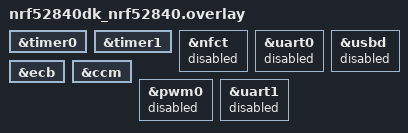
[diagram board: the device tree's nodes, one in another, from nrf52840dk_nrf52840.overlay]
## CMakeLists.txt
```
cmake_minimum_required(VERSION 3.20.0)
find_package(Zephyr REQUIRED HINTS $ENV{ZEPHYR_BASE})

project(periodic_adv_sender)

target_sources(app PRIVATE src/main.c src/saadc_helpers.c src/timer_helpers.c src/bt_helpers.c)
```

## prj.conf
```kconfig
CONFIG_BT=y
CONFIG_BT_BROADCASTER=y
CONFIG_BT_EXT_ADV=y
CONFIG_BT_PER_ADV=y
CONFIG_BT_DEVICE_NAME="harry"
CONFIG_BT_PER_ADV_SYNC_TRANSFER_SENDER=y
CONFIG_BT_PER_ADV_RSP=y

CONFIG_BT_MAX_CONN=1
CONFIG_BT_CENTRAL=y
CONFIG_BT_PRIVACY=y
CONFIG_BT_SMP=y

CONFIG_BT_CTLR_TX_PWR_MINUS_20=y

# Config SAADC
#CONFIG_GPIO=n
CONFIG_NRFX_GPIOTE=y
CONFIG_NRFX_SAADC=y


# Config Timers
CONFIG_NRFX_TIMER0=y
CONFIG_NRFX_TIMER1=y


# power saving stuff
CONFIG_LOG=n
CONFIG_SERIAL=n
CONFIG_TFM_LOG_LEVEL_SILENCE=y


# Enable system power management
CONFIG_PM=y
CONFIG_PM_DEVICE=y



#DEBUG
#CONFIG_DEBUG_THREAD_INFO=y
#CONFIG_DEBUG_INFO=y
#CONFIG_THREAD_RUNTIME_STATS=y
#CONFIG_DEBUG_OPTIMIZATIONS=y
#CONFIG_ASSERT=y
#CONFIG_THREAD_NAME=y
#CONFIG_THREAD_ANALYZER=y
#CONFIG_THREAD_MONITOR=y

# enable uart driver
#CONFIG_SERIAL=y

# enable console
#CONFIG_CONSOLE=y
#CONFIG_UART_CONSOLE=y

# Enable RTT
#CONFIG_USE_SEGGER_RTT=y




# Enable minimal libc
CONFIG_MINIMAL_LIBC=y
CONFIG_MINIMAL_LIBC_MALLOC=y
# Set the malloc arena size to a non-zero value
CONFIG_MINIMAL_LIBC_MALLOC_ARENA_SIZE=1024
```

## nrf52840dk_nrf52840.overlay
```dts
// To get started, press Ctrl+Space to bring up the completion menu and view the available nodes.

// You can also use the buttons in the sidebar to perform actions on nodes.
// Actions currently available include:

// * Enabling / disabling the node
// * Adding the bus to a bus
// * Removing the node
// * Connecting ADC channels

// For more help, browse the DeviceTree documentation at https://docs.zephyrproject.org/latest/guides/dts/index.html
// You can also visit the nRF DeviceTree extension documentation at https://docs.nordicsemi.com/bundle/nrf-connect-vscode/page/guides/ncs_configure_app.html#devicetree-support-in-the-extension

&timer0 {
	status = "okay";
};

&timer1 {
	status = "okay";
};

// was disabled
&nfct {
	status = "disabled";
};

// was disabled
&uart0 {
	status = "disabled";
};

// was disabled
&usbd {
	status = "disabled";
};

// was okay
&ecb {
	status = "okay";
};

// was okay
&ccm {
	status = "okay";
};

// was disabled
&pwm0 {
	status = "disabled";
};

// was disabled
&uart1 {
	status = "disabled";
};
```

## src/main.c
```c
/*
 * Copyright (c) 2023 Nordic Semiconductor ASA
 *
 * SPDX-License-Identifier: Apache-2.0
 */

#include "timer_helpers.h"
#include "bt_helpers.h"
#include "saadc_helpers.h"
#include <stdlib.h>
#include <ram_pwrdn.h>
#include <zephyr/pm/device.h>

/*
================================
=#=#=#= Global Variables =#=#=#=
================================
*/

uint8_t backing_store[NUM_SUBEVENTS][PACKET_SIZE];


BUILD_ASSERT(ARRAY_SIZE(backing_store) == ARRAY_SIZE(subevent_data_params));



/*
================================
=#=#=#= HELPER FUNCTIONS =#=#=#=
================================
*/


void saadc_sample() {
	saadc_result res_se = {CHANNEL_COUNT_SE, malloc(sizeof(saadc_result) * CHANNEL_COUNT_SE)};
	sample_saadc(SE, &res_se);
	int i = 0;
	/*
	while(i < res_se.nchannels) {
		backing_store[i][0] = (uint8_t) i;
		backing_store[i][1] = (uint8_t) res_se.values[i];
		printk("Channel %d: %d\n", i, (int) res_se.values[i]);
		i++;
	}*/
	

	backing_store[0][0] = (uint8_t) res_se.values[0]; // ADC channel 0
	backing_store[0][1] = (uint8_t) res_se.values[1]; // ADC channel 1
	backing_store[0][2] = (uint8_t) res_se.values[2]; // ADC channel 2
	backing_store[0][3] = (uint8_t) res_se.values[3]; // ADC channel 3

	while(i < res_se.nchannels) {
		int val = res_se.values[i];
		printk("SINGLE ENDED - Channel %d: %d (%d V, or %d mV)\n", i, (int) val, to_volts(val), to_millivolts(val));
		i++;
	}

	saadc_result res_diff = {CHANNEL_COUNT_SE, malloc(sizeof(saadc_result) * CHANNEL_COUNT_DIFF)};

	sample_saadc(DIFF, &res_diff);

	backing_store[0][4] = (uint8_t) res_diff.values[0]; // ADC channels 0 & 1
	backing_store[0][5] = (uint8_t) res_diff.values[1]; // ADC channels 2 & 3
	backing_store[0][6] = (uint8_t) res_diff.values[2]; // ADC channels 4 & 5
	backing_store[0][7] = (uint8_t) res_diff.values[3]; // ADC channels 6 & 7


	i = 0;
	while(i < res_diff.nchannels) {
		// Offset by the number of channels in the single-ended sample
		//backing_store[i + res_se.nchannels][0] = (uint8_t) i;
		//backing_store[i + res_se.nchannels][1] = (uint8_t) res_diff.values[i];
		printk("DIFFERENTIAL - Channel %d: %d\n", i, (int) res_diff.values[i]);
		i++;
	}
}

int main(void) {
	//nrf_uart_disable(NRF_UART0);

//	const auto * qspi_dev = DEVICE_DT_GET(DT_INST(0, nordic_qspi_nor));
//	if (device_is_ready(qspi_dev))
//	{
//		// Put the peripheral into suspended state.
//		pm_device_action_run(qspi_dev, PM_DEVICE_ACTION_SUSPEND);
//	}


	nrfx_timer_t timer = NRFX_TIMER_INSTANCE(TIMER_INST_IDX);
	nrfx_timer_config_t config = NRFX_TIMER_DEFAULT_CONFIG;
	config.bit_width = NRF_TIMER_BIT_WIDTH_32;
	bool flag = 0;
	config.p_context = &flag;
	/*{
		.frequency = NRF_TIMER_FREQ_16MHz,         						///< Frequency.
		.mode = NRF_TIMER_MODE_TIMER,           					    ///< Mode of operation.
		.bit_width = NRF_TIMER_BIT_WIDTH_32,        				  	///< Bit width.
		.interrupt_priority = NRFX_TIMER_DEFAULT_CONFIG_IRQ_PRIORITY, 	///< Interrupt priority.
		.p_context = NULL												///< Context passed to interrupt handler.
	};*/
	
	saadc_sample();
	k_sleep(K_MSEC(400));

	bool err = initialise_bt(backing_store);
	if (err) return 1;

	k_sleep(K_MSEC(800));

	timer_setup(&timer, &config);

	while (true) {
		if (flag) {
			saadc_sample();
			update_bufs(backing_store);
			k_sleep(K_MSEC(5000));
			flag = 0;
			//bt_disable();
		}
		k_sleep(K_MSEC(5000));
		//power_down_unused_ram();
	}

	return 0;
}
```

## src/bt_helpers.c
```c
/*
 * Copyright (c) 2023 Nordic Semiconductor ASA
 *
 * SPDX-License-Identifier: Apache-2.0
 */


#include "bt_helpers.h"


const struct bt_le_per_adv_param per_adv_params = {
	.interval_min = PER_ADV_INTERVAL,
	.interval_max = PER_ADV_INTERVAL,
	.options = 0, //(BT_LE_PER_ADV_OPT_USE_TX_POWER | BT_LE_PER_ADV_OPT_INCLUDE_ADI),
	.num_subevents = NUM_SUBEVENTS,
	.subevent_interval = SUBEVENT_INTERVAL,
	.response_slot_delay = 0x5,
	.response_slot_spacing = 0x50,
	.num_response_slots = NUM_RSP_SLOTS,
};

const struct bt_le_adv_param* adv_params = BT_LE_EXT_ADV_NCONN_NAME; //BT_LE_ADV_PARAM((BT_LE_ADV_OPT_EXT_ADV | BT_LE_ADV_OPT_USE_NAME), ADVERTISING_INTERVAL, ADVERTISING_INTERVAL, NULL);

struct bt_conn *default_conn;
struct net_buf_simple bufs[NUM_SUBEVENTS];
struct bt_le_per_adv_subevent_data_params subevent_data_params[NUM_SUBEVENTS];

BUILD_ASSERT(ARRAY_SIZE(bufs) == ARRAY_SIZE(subevent_data_params));

// Function to handle the request for data from the receiver.
void request_cb(struct bt_le_ext_adv *adv, const struct bt_le_per_adv_data_request *request) {
	int err;
	uint8_t to_send;

	/* Continuously send the data in bufs and listen to all response slots */

	to_send = MIN(request->count, ARRAY_SIZE(subevent_data_params));
	for (size_t i = 0; i < to_send; i++) {
		subevent_data_params[i].subevent =
			(request->start + i) % per_adv_params.num_subevents;
		subevent_data_params[i].response_slot_start = 0;
		subevent_data_params[i].response_slot_count = NUM_RSP_SLOTS;
		subevent_data_params[i].data = &bufs[i];
	}

	err = bt_le_per_adv_set_subevent_data(adv, to_send, subevent_data_params);
	if (err) {
		printk("Failed to set subevent data (err %d)\n", err);
	}
}

bool get_address(struct bt_data *data, void *user_data) {
	bt_addr_le_t *addr = user_data;

	if (data->type == BT_DATA_LE_BT_DEVICE_ADDRESS) {
		memcpy(addr->a.val, data->data, sizeof(addr->a.val));
		addr->type = data->data[sizeof(addr->a)];

		return false;
	}

	return true;
}

void response_cb(struct bt_le_ext_adv *adv, struct bt_le_per_adv_response_info *info,
			struct net_buf_simple *buf)
{
	int err;
	bt_addr_le_t peer;
	char addr_str[BT_ADDR_LE_STR_LEN];
	struct bt_conn_le_create_synced_param synced_param;
	struct bt_le_conn_param conn_param;

	if (!buf) {
		return;
	}

	if (default_conn) {
		/* Do not initiate new connections while already connected */
		return;
	}

	bt_addr_le_copy(&peer, &bt_addr_le_none);
	bt_data_parse(buf, get_address, &peer);
	if (bt_addr_le_eq(&peer, &bt_addr_le_none)) {
		/* No address found */
		return;
	}

	bt_addr_le_to_str(&peer, addr_str, sizeof(addr_str));
	printk("Connecting to %s in subevent %d\n", addr_str, info->subevent);

	synced_param.peer = &peer;
	synced_param.subevent = info->subevent;

	/* Choose same interval as PAwR advertiser to avoid scheduling conflicts */
	conn_param.interval_min = SUBEVENT_INTERVAL;
	conn_param.interval_max = SUBEVENT_INTERVAL;

	/* Default values */
	conn_param.latency = 0;
	conn_param.timeout = 400;

	err = bt_conn_le_create_synced(adv, &synced_param, &conn_param, &default_conn);
	if (err) {
		printk("Failed to initiate connection (err %d)", err);
	}
	//bt_le_adv_stop();
}

const struct bt_le_ext_adv_cb adv_cb = {
	.pawr_data_request = request_cb,
	.pawr_response = response_cb,
};

void connected_cb(struct bt_conn *conn, uint8_t err)
{
	printk("Connected (err 0x%02X)\n", err);

	__ASSERT(conn == default_conn, "Unexpected connected callback");

	if (err) {
		bt_conn_unref(default_conn);
		default_conn = NULL;
	}
}

void disconnected_cb(struct bt_conn *conn, uint8_t reason)
{
	printk("Disconnected (reason 0x%02X)\n", reason);

	__ASSERT(conn == default_conn, "Unexpected disconnected callback");

	bt_conn_unref(default_conn);
	default_conn = NULL;
}

BT_CONN_CB_DEFINE(conn_cb) = {
	.connected = connected_cb,
	.disconnected = disconnected_cb,
};

void init_bufs(uint8_t backing_store[NUM_SUBEVENTS][PACKET_SIZE])
{
	/* Set up data to send */
	for (size_t i = 0; i < NUM_SUBEVENTS; i++) {
		net_buf_simple_init_with_data(&bufs[i], &backing_store[i],
					      PACKET_SIZE);
	}
}

// resets the buffer and reinitialises it with new backing store data
void update_bufs(uint8_t backing_store[NUM_SUBEVENTS][PACKET_SIZE]) {
    for (size_t i = 0; i < NUM_SUBEVENTS; i++) {
        net_buf_simple_reset(&bufs[i]);
        init_bufs(backing_store);
    }
}

// Function to initialise the Bluetooth subsystem.
bool initialise_bt(uint8_t backing_store[NUM_SUBEVENTS][PACKET_SIZE]) {
	int err;
	struct bt_le_ext_adv *pawr_adv;

	init_bufs(backing_store);

	/* Initialize the Bluetooth Subsystem */
	err = bt_enable(NULL);
	if (err) {
		printk("Bluetooth init failed (err %d)\n", err);
		return 1;
	}

	/* Create a non-connectable non-scannable advertising set */
	err = bt_le_ext_adv_create(adv_params, &adv_cb, &pawr_adv);
	if (err) {
		printk("Failed to create advertising set (err %d)\n", err);
		return 1;
	}

	/* Set periodic advertising parameters */
	err = bt_le_per_adv_set_param(pawr_adv, &per_adv_params);
	if (err) {
		printk("Failed to set periodic advertising parameters (err %d)\n", err);
		return 1;
	}

	/* Enable Periodic Advertising */
	err = bt_le_per_adv_start(pawr_adv);
	if (err) {
		printk("Failed to enable periodic advertising (err %d)\n", err);
		return 1;
	}

	printk("Start Periodic Advertising\n");
	err = bt_le_ext_adv_start(pawr_adv, BT_LE_EXT_ADV_START_DEFAULT);
	if (err) {
		printk("Failed to start extended advertising (err %d)\n", err);
		return 1;
	}
	return 0;
}
```

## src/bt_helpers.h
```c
#include <zephyr/bluetooth/bluetooth.h>
#include <zephyr/bluetooth/conn.h>
#include <zephyr/bluetooth/gap.h>
#include <zephyr/sys/util.h>
#include <zephyr/net/buf.h>


#define NUM_RSP_SLOTS	  4
#define NUM_SUBEVENTS	  4
#define PACKET_SIZE		  8
#define SUBEVENT_INTERVAL 0x30
#define ADVERTISING_INTERVAL BT_GAP_ADV_FAST_INT_MIN_2
#define PER_ADV_INTERVAL 0x100

extern struct bt_conn *default_conn;
extern struct net_buf_simple bufs[NUM_SUBEVENTS];

// change these to alter the advertising interval
extern const struct bt_le_per_adv_param per_adv_params;
extern const struct bt_le_adv_param* adv_params;

extern struct bt_le_per_adv_subevent_data_params subevent_data_params[NUM_SUBEVENTS];


// Function declarations
void request_cb(struct bt_le_ext_adv *adv, const struct bt_le_per_adv_data_request *request);
bool get_address(struct bt_data *data, void *user_data);
void response_cb(struct bt_le_ext_adv *adv, struct bt_le_per_adv_response_info *info, struct net_buf_simple *buf);
void connected_cb(struct bt_conn *conn, uint8_t err);
void disconnected_cb(struct bt_conn *conn, uint8_t reason);
void init_bufs(uint8_t backing_store[NUM_SUBEVENTS][PACKET_SIZE]);
void update_bufs(uint8_t backing_store[NUM_SUBEVENTS][PACKET_SIZE]);
bool initialise_bt(uint8_t backing_store[NUM_SUBEVENTS][PACKET_SIZE]);
```

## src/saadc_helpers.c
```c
/*
 * Copyright (c) 2022 - 2023, Nordic Semiconductor ASA
 * All rights reserved.
 *
 * SPDX-License-Identifier: BSD-3-Clause
 *
 * Redistribution and use in source and binary forms, with or without
 * modification, are permitted provided that the following conditions are met:
 *
 * 1. Redistributions of source code must retain the above copyright notice, this
 *    list of conditions and the following disclaimer.
 *
 * 2. Redistributions in binary form must reproduce the above copyright
 *    notice, this list of conditions and the following disclaimer in the
 *    documentation and/or other materials provided with the distribution.
 *
 * 3. Neither the name of the copyright holder nor the names of its
 *    contributors may be used to endorse or promote products derived from this
 *    software without specific prior written permission.
 *
 * THIS SOFTWARE IS PROVIDED BY THE COPYRIGHT HOLDERS AND CONTRIBUTORS "AS IS"
 * AND ANY EXPRESS OR IMPLIED WARRANTIES, INCLUDING, BUT NOT LIMITED TO, THE
 * IMPLIED WARRANTIES OF MERCHANTABILITY AND FITNESS FOR A PARTICULAR PURPOSE
 * ARE DISCLAIMED. IN NO EVENT SHALL THE COPYRIGHT HOLDER OR CONTRIBUTORS BE
 * LIABLE FOR ANY DIRECT, INDIRECT, INCIDENTAL, SPECIAL, EXEMPLARY, OR
 * CONSEQUENTIAL DAMAGES (INCLUDING, BUT NOT LIMITED TO, PROCUREMENT OF
 * SUBSTITUTE GOODS OR SERVICES; LOSS OF USE, DATA, OR PROFITS; OR BUSINESS
 * INTERRUPTION) HOWEVER CAUSED AND ON ANY THEORY OF LIABILITY, WHETHER IN
 * CONTRACT, STRICT LIABILITY, OR TORT (INCLUDING NEGLIGENCE OR OTHERWISE)
 * ARISING IN ANY WAY OUT OF THE USE OF THIS SOFTWARE, EVEN IF ADVISED OF THE
 * POSSIBILITY OF SUCH DAMAGE.
 */

#include "saadc_helpers.h"


static void _setup_se(void) {

    nrfx_err_t status = nrfx_saadc_init(NRFX_SAADC_DEFAULT_CONFIG_IRQ_PRIORITY);
    NRFX_ASSERT(status == NRFX_SUCCESS);

    status = nrfx_saadc_channels_config(m_multiple_channels_se, CHANNEL_COUNT_SE);
    NRFX_ASSERT(status == NRFX_SUCCESS);

    uint32_t channels_mask = nrfx_saadc_channels_configured_get();
    status = nrfx_saadc_simple_mode_set(channels_mask,
                                    NRF_SAADC_RESOLUTION_12BIT,
                                    NRF_SAADC_OVERSAMPLE_DISABLED,
                                    NULL);
    NRFX_ASSERT(status == NRFX_SUCCESS);

    status = nrfx_saadc_buffer_set(m_samples_buffer_se, CHANNEL_COUNT_SE);
    NRFX_ASSERT(status == NRFX_SUCCESS);

    return;
}


static void _setup_diff(void) {

    nrfx_err_t status = nrfx_saadc_init(NRFX_SAADC_DEFAULT_CONFIG_IRQ_PRIORITY);
    NRFX_ASSERT(status == NRFX_SUCCESS);

    status = nrfx_saadc_channels_config(m_multiple_channels_diff, CHANNEL_COUNT_DIFF);
    NRFX_ASSERT(status == NRFX_SUCCESS);

    uint32_t channels_mask = nrfx_saadc_channels_configured_get();
    status = nrfx_saadc_simple_mode_set(channels_mask,
                                    NRF_SAADC_RESOLUTION_8BIT,
                                    NRF_SAADC_OVERSAMPLE_DISABLED,
                                    NULL);
    NRFX_ASSERT(status == NRFX_SUCCESS);

    status = nrfx_saadc_buffer_set(m_samples_buffer_diff, CHANNEL_COUNT_DIFF);
    NRFX_ASSERT(status == NRFX_SUCCESS);

    return;
}


void sample_se(saadc_result* res) {

    _setup_se();

    nrfx_err_t status = nrfx_saadc_offset_calibrate(NULL);
    NRFX_ASSERT(status == NRFX_SUCCESS);

    status = nrfx_saadc_mode_trigger();

    NRFX_ASSERT(status == NRFX_SUCCESS);
    int i;
    for (i = 0; i < CHANNEL_COUNT_SE; i++)
    {
        res->values[i] = m_samples_buffer_se[i];
    }
    nrfx_saadc_uninit();
    return;
}

void sample_diff(saadc_result* res) {

    _setup_diff();

    nrfx_err_t status = nrfx_saadc_offset_calibrate(NULL);
    NRFX_ASSERT(status == NRFX_SUCCESS);


    status = nrfx_saadc_mode_trigger();
    NRFX_ASSERT(status == NRFX_SUCCESS);
    int i;
    for (i = 0; i < CHANNEL_COUNT_DIFF; i++)
    {
        res->values[i] = m_samples_buffer_diff[i];
    }
    nrfx_saadc_uninit();
    return;
}

void sample_saadc(int mode, saadc_result* res) {

    if (mode == SE) {
        sample_se(res);
    } else if (mode == DIFF) {
        sample_diff(res);
    }

    return;
}

uint8_t to_millivolts(nrf_saadc_value_t value) {
    return (uint8_t) (2<<12)*1000*value*(1/6)*(1/0.6);
}

uint8_t to_volts(nrf_saadc_value_t value) {
    return (uint8_t) (2<<12)*value*(1/6)*(1/0.6);
}

uint8_t to_microamps(nrf_saadc_value_t value) {
    return (uint8_t) (2<<12)*1000*1000*value*(1/6)*(1/0.6)*(1/RESISTOR);
}

uint8_t to_milliamps(nrf_saadc_value_t value) {
    return (uint8_t) (2<<12)*1000*value*(1/6)*(1/0.6)*(1/RESISTOR);
}
```

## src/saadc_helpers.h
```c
/*
 * Copyright (c) 2022 - 2023, Nordic Semiconductor ASA
 * All rights reserved.
 *
 * SPDX-License-Identifier: BSD-3-Clause
 *
 * Redistribution and use in source and binary forms, with or without
 * modification, are permitted provided that the following conditions are met:
 *
 * 1. Redistributions of source code must retain the above copyright notice, this
 *    list of conditions and the following disclaimer.
 *
 * 2. Redistributions in binary form must reproduce the above copyright
 *    notice, this list of conditions and the following disclaimer in the
 *    documentation and/or other materials provided with the distribution.
 *
 * 3. Neither the name of the copyright holder nor the names of its
 *    contributors may be used to endorse or promote products derived from this
 *    software without specific prior written permission.
 *
 * THIS SOFTWARE IS PROVIDED BY THE COPYRIGHT HOLDERS AND CONTRIBUTORS "AS IS"
 * AND ANY EXPRESS OR IMPLIED WARRANTIES, INCLUDING, BUT NOT LIMITED TO, THE
 * IMPLIED WARRANTIES OF MERCHANTABILITY AND FITNESS FOR A PARTICULAR PURPOSE
 * ARE DISCLAIMED. IN NO EVENT SHALL THE COPYRIGHT HOLDER OR CONTRIBUTORS BE
 * LIABLE FOR ANY DIRECT, INDIRECT, INCIDENTAL, SPECIAL, EXEMPLARY, OR
 * CONSEQUENTIAL DAMAGES (INCLUDING, BUT NOT LIMITED TO, PROCUREMENT OF
 * SUBSTITUTE GOODS OR SERVICES; LOSS OF USE, DATA, OR PROFITS; OR BUSINESS
 * INTERRUPTION) HOWEVER CAUSED AND ON ANY THEORY OF LIABILITY, WHETHER IN
 * CONTRACT, STRICT LIABILITY, OR TORT (INCLUDING NEGLIGENCE OR OTHERWISE)
 * ARISING IN ANY WAY OUT OF THE USE OF THIS SOFTWARE, EVEN IF ADVISED OF THE
 * POSSIBILITY OF SUCH DAMAGE.
 */


#include <nrfx_gpiote.h>
#include <nrfx_saadc.h>


/**
 * @brief SAADC channel default configuration for the single-ended mode.
 *
 * This configuration sets up single-ended SAADC channel with the following options:
 * - resistor ladder disabled
 * - gain: 1/6
 * - reference voltage: internal 0.6 V
 * - sample acquisition time: 10 us
 * - burst disabled
 *
 * @param[in] _pin_p Positive input analog pin.
 * @param[in] _index Channel index.
 *
 * @sa nrfx_saadc_channel_t
 */
#define SAADC_CHANNEL_SE(_pin_p, _index)       \
{                                                           \
    .channel_config =                                       \
    {                                                       \
        .resistor_p = NRF_SAADC_RESISTOR_DISABLED,          \
        .resistor_n = NRF_SAADC_RESISTOR_DISABLED,          \
        .gain       = NRF_SAADC_GAIN1_6,                    \
        .reference  = NRF_SAADC_REFERENCE_INTERNAL,         \
        .acq_time   = NRF_SAADC_ACQTIME_10US,               \
        .mode       = NRF_SAADC_MODE_SINGLE_ENDED,          \
        .burst      = NRF_SAADC_BURST_DISABLED,             \
    },                                                      \
    .pin_p          = (nrf_saadc_input_t)_pin_p,            \
    .pin_n          = NRF_SAADC_INPUT_DISABLED,             \
    .channel_index  = _index,                               \
}


/**
 * @brief SAADC channel configuration for the differential mode.
 *
 * This configuration sets up differential SAADC channel with the following options:
 * - resistor ladder disabled
 * - gain: 1/6
 * - reference voltage: internal 0.6 V
 * - sample acquisition time: 10 us
 * - burst disabled
 *
 * @param[in] _pin_p Positive input analog pin.
 * @param[in] _pin_n Negative input analog pin.
 * @param[in] _index Channel index.
 *
 * @sa nrfx_saadc_channel_t
 */
#define SAADC_CHANNEL_DIFFERENTIAL(_pin_p, _pin_n, _index) \
{                                                                       \
    .channel_config =                                                   \
    {                                                                   \
        .resistor_p = NRF_SAADC_RESISTOR_DISABLED,                      \
        .resistor_n = NRF_SAADC_RESISTOR_DISABLED,                      \
        .gain       = NRF_SAADC_GAIN1_6,                                \
        .reference  = NRF_SAADC_REFERENCE_INTERNAL,                     \
        .acq_time   = NRF_SAADC_ACQTIME_10US,                           \
        .mode       = NRF_SAADC_MODE_DIFFERENTIAL,                      \
        .burst      = NRF_SAADC_BURST_DISABLED,                         \
    },                                                                  \
    .pin_p          = (nrf_saadc_input_t)_pin_p,                        \
    .pin_n          = (nrf_saadc_input_t)_pin_n,                        \
    .channel_index  = _index,                                           \
}


/** SAADC channel differential configuration structure for multiple channel use. */
static const nrfx_saadc_channel_t m_multiple_channels_diff[] =
{
    SAADC_CHANNEL_DIFFERENTIAL(NRF_SAADC_INPUT_AIN0, NRF_SAADC_INPUT_AIN1, 0),
    SAADC_CHANNEL_DIFFERENTIAL(NRF_SAADC_INPUT_AIN2, NRF_SAADC_INPUT_AIN3, 1),
    SAADC_CHANNEL_DIFFERENTIAL(NRF_SAADC_INPUT_AIN4, NRF_SAADC_INPUT_AIN5, 2),
    SAADC_CHANNEL_DIFFERENTIAL(NRF_SAADC_INPUT_AIN6, NRF_SAADC_INPUT_AIN7, 3)
};

/** SAADC channel single-ended configuration structure for multiple channel use. */
static const nrfx_saadc_channel_t m_multiple_channels_se[] =
{
    SAADC_CHANNEL_SE(NRF_SAADC_INPUT_AIN0, 0),
    SAADC_CHANNEL_SE(NRF_SAADC_INPUT_AIN2, 1),
    SAADC_CHANNEL_SE(NRF_SAADC_INPUT_AIN4, 2),
    SAADC_CHANNEL_SE(NRF_SAADC_INPUT_AIN6, 3)
};

/** @brief Symbol specifying numbers of multiple channels ( @ref m_multiple_channels) used by SAADC. */
#define CHANNEL_COUNT_SE NRFX_ARRAY_SIZE(m_multiple_channels_se)
#define CHANNEL_COUNT_DIFF NRFX_ARRAY_SIZE(m_multiple_channels_diff)

/** @brief Array specifying GPIO pins used to test the functionality of SAADC. */
//static uint8_t m_out_pins[CHANNEL_COUNT] = {LOOPBACK_PIN_1B, LOOPBACK_PIN_2B, LOOPBACK_PIN_3B};

/** @brief Samples buffer defined with the size of @ref CHANNEL_COUNT symbol to store values from each channel ( @ref m_multiple_channels). */
static nrf_saadc_value_t m_samples_buffer_se[CHANNEL_COUNT_SE];
static nrf_saadc_value_t m_samples_buffer_diff[CHANNEL_COUNT_DIFF];

/** @brief Symbol specifying the number of SAADC samplings to trigger. */
#define SAMPLING_ITERATIONS 1
#define RESISTOR 100


typedef struct saadc_result {
    uint8_t nchannels;
    nrf_saadc_value_t* values;
} saadc_result;


// Enum for selecting SAADC mode
enum mode {
    SE,
    DIFF
};

void sample_se(saadc_result* res);

void sample_diff(saadc_result* res);

void sample_saadc(int mode, saadc_result* res);

uint8_t to_millivolts(nrf_saadc_value_t value);

uint8_t to_volts(nrf_saadc_value_t value);

uint8_t to_microamps(nrf_saadc_value_t value);

uint8_t to_milliamps(nrf_saadc_value_t value);
```

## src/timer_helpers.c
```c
#include "timer_helpers.h"
#include <zephyr/irq.h>


void timer_handler(nrf_timer_event_t event_type, void * p_context) {
	bool* flag = (bool*) p_context;
	if(!*flag) *flag = 1;
}


void timer_setup(nrfx_timer_t* timer, nrfx_timer_config_t* config) {

	nrfx_err_t status = nrfx_timer_init(timer, config, timer_handler);
    NRFX_ASSERT(status == NRFX_SUCCESS);


#if defined(__ZEPHYR__)
    IRQ_DIRECT_CONNECT(NRFX_IRQ_NUMBER_GET(NRF_TIMER_INST_GET(TIMER_INST_IDX)), IRQ_PRIO_LOWEST,
                       NRFX_TIMER_INST_HANDLER_GET(TIMER_INST_IDX), 0);
#endif

	nrfx_timer_clear(timer);

	// Creating variable desired_ticks to store the output of nrfx_timer_ms_to_ticks function
	uint32_t desired_ticks = nrfx_timer_ms_to_ticks(timer, DESIRED_MS_DELAY);

	// Setting the timer channel NRF_TIMER_CC_CHANNEL0 in the extended compare mode to stop the timer and
	// trigger an interrupt if internal counter register is equal to desired_ticks.
	nrfx_timer_extended_compare(timer, NRF_TIMER_CC_CHANNEL1, desired_ticks,
								NRF_TIMER_SHORT_COMPARE1_CLEAR_MASK, true);

	nrfx_timer_enable(timer);
}
```

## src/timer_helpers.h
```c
#include <nrfx_timer.h>


/** @brief Symbol specifying timer instance to be used. */
#define TIMER_INST_IDX 1
#define DESIRED_MS_DELAY 25000

void timer_handler(nrf_timer_event_t event_type, void * p_context);
void timer_setup(nrfx_timer_t* timer, nrfx_timer_config_t* config);
```
